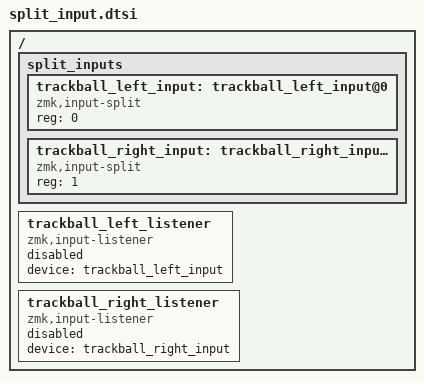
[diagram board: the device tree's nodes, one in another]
/*
    @bravekarma suggests putting *split* input device & input listener nodes here.

    The input listener that is used by the central side is added here but disabled by default.
    This is so that keymaps (which are included for both central and peripheral builds) can reference the listener to add input processors without failing with an undefined reference error.
    About input split device: https://zmk.dev/docs/development/hardware-integration/pointing#shared-configuration-1
*/

/ {
    split_inputs {
        #address-cells = <1>;
        #size-cells = <0>;

        trackball_left_input: trackball_left_input@0 {
            compatible = "zmk,input-split";
            reg = <0>;
        };

        trackball_right_input: trackball_right_input@1 {
            compatible = "zmk,input-split";
            reg = <1>;
        };
    };

    trackball_left_listener: trackball_left_listener {
        compatible = "zmk,input-listener";
        status = "disabled";
        device = <&trackball_left_input>;
    };

    trackball_right_listener: trackball_right_listener {
        compatible = "zmk,input-listener";
        status = "disabled";
        device = <&trackball_right_input>;
    };
};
